# TC37XPD register map
Vendor: Infineon; Series: ATVMC; File version: 100
CPU: other r0p0, little endian, MPU, FPU, vendor SysTick, 4 interrupt priority bits
Registers are 32-bit, read-write, reset 0x0 unless marked. A register's access mark holds for its fields unless they carry their own. Offsets are from the block's base; [hi:lo] are bit positions; {n}, {i} and the like mark numbered series.

## ERAY0 (part 3 of 3) — ERAY
Base 0xF001C000
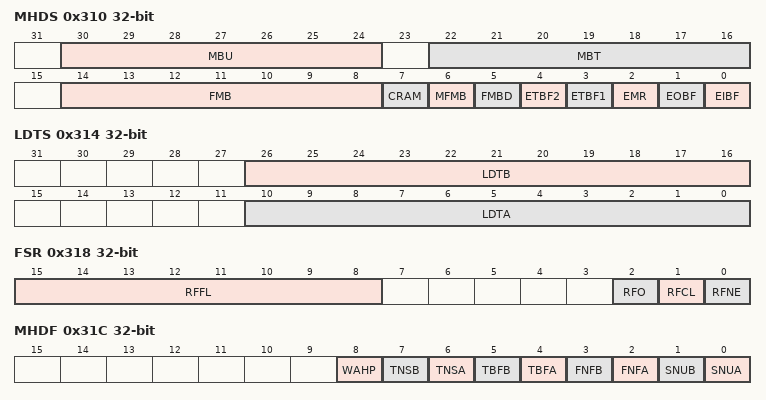
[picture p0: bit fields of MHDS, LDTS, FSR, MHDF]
0x310 MHDS access per field — Message Handler Status resetvalue={Application Reset:0x0}
  [30:24] MBU ro — Message Buffer Updated MBU. Number of Message Buffer that was updated last. For this Message Buffer the respective NDn n 0 31 to NDn n 96 127 and or MBCn n 0 31 to MBCn n 96 127 flag in the New Data Registers NDAT1 to NDAT4 and the Message Buffer Status Changed MBSC1 to MBSC4 registers are also set. MBU is reset when the Communication Controller leaves CONFIG state or enters STARTUP state.
  [22:16] MBT ro — Message Buffer Transmitted MBT. Number of last successfully transmitted Message Buffer. If the Message Buffer is configured for single shot mode the respective TXR flag in the Transmission Request Registers TXRQ1 to TXRQ4 was reset. MBT is reset when the Communication Controller leaves CONFIG state or enters STARTUP state.
  [14:8] FMB ro — Faulty Message Buffer FMB. ECC error occurred when reading from the Message Buffer or when transferring data from Input Buffer or Transient Buffer A or Transient Buffer B to the Message Buffer referenced by MHDS.FMB. Value only valid when one of the flags MHDS.EIBF MHDS.EMR MHDS.ETBF1 MHDS.ETBF2 and flag MHDS.FMBD is set. Updated only after the Host has reset flag MHDS.FMBD.
  [7] CRAM ro — Clear all internal RAM s CRAM. Signals that execution of the CHI command CLEAR RAMS is ongoing all bits of all internal RAM blocks are written to 0 . The bit is set by CHI command CLEAR RAMS.
  [6] MFMB rw — Multiple Faulty Message Buffers detected MFMB
  [5] FMBD rw — Faulty Message Buffer Detected FMBD
  [4] ETBF2 rw — ECC Error Transient Buffer RAM B ETBF2
  [3] ETBF1 rw — ECC Error Transient Buffer RAM A ETBF1
  [2] EMR rw — ECC Error Message RAM EMR
  [1] EOBF rw — ECC Error Output Buffer RAM 1 2 EOBF
  [0] EIBF rw — ECC Error Input Buffer RAM 1 2 EIBF
0x314 LDTS ro — Last Dynamic Transmit Slot resetvalue={Application Reset:0x0}
  [26:16] LDTB — Last Dynamic Transmission Channel B LDTB. Value of vSlotCounter B at the time of the last Frame transmission on channel B in the dynamic segment of this node. It is updated at the end of the dynamic segment and is reset to zero if no Frame was transmitted during the dynamic segment.
  [10:0] LDTA — Last Dynamic Transmission Channel A LDTA. Value of vSlotCounter A at the time of the last Frame transmission on channel A in the dynamic segment of this node. It is updated at the end of the dynamic segment and is reset to zero if no Frame was transmitted during the dynamic segment.
0x318 FSR ro — FIFO Status Register resetvalue={Application Reset:0x0}
  [15:8] RFFL — Receive FIFO Fill Level RFFL. Number of FIFO buffers filled up with new data not yet read by the Host. Maximum value is 128.
  [2] RFO — Receive FIFO Overrun RFO. The flag is set by the Communication Controller when a receive FIFO overrun is detected. When a receive FIFO overrun occurs the oldest message is overwritten with the actual received message. In addition service request flag EIR.RFO is set.The flag is cleared by the next FIFO read access issued by the Host.
  [1] RFCL — Receive FIFO Critical Level RFCL. This flag is set when the receive FIFO fill level RFFL is equal or greater than the critical level as configured by FCL.CL. The flag is cleared by the Communication Controller as soon as RFFL drops below FCL.CL. When RFCL changes from 0 to 1 bit SIR.RFCL is set to 1 and if enabled an service request is generated.
  [0] RFNE — Receive FIFO Not Empty RFNE. This flag is set by the Communication Controller when a received valid Frame data or NULL Frame depending on rejection mask was stored in the FIFO. In addition service request flag SIR.RFNE is set. The bit is reset after the Host has read all message from the FIFO.
0x31C MHDF — Message Handler Constraints Flags resetvalue={Application Reset:0x0}
  [8] WAHP — Write Attempt to Header Partition WAHP. Outside DEFAULT CONFIG and CONFIG state this flag is set by the Communication Controller when the message handler tries to write message data into the Header Partition of the Message RAM due to faulty configuration of a Message Buffer. The write attempt is not executed to protect the Header Partition from unintended write accesses.
  [7] TNSB — Transmission Not Started Channel B TNSB. This flag is set by the CC when the Message Handler was not ready to start a scheduled transmission on channel B at the action point of the configured slot.
  [6] TNSA — Transmission Not Started Channel A TNSA. This flag is set by the CC when the Message Handler was not ready to start a scheduled transmission on channel A at the action point of the configured slot.
  [5] TBFB — Transient Buffer Access Failure B TBFB. This flag is set by the Communication Controller when a read or write access to Transient Buffer B requested by PRT B could not complete within the available time.
  [4] TBFA — Transient Buffer Access Failure A TBFA. This flag is set by the Communication Controller when a read or write access to Transient Buffer A requested by PRT A could not complete within the available time.
  [3] FNFB — Find Sequence Not Finished Channel B FNFB. This flag is set by the Communication Controller when the Message Handler due to overload condition was not able to finish a find sequence scan of Message RAM for matching Message Buffer with respect to channel B.
  [2] FNFA — Find Sequence Not Finished Channel A FNFA. This flag is set by the Communication Controller when the Message Handler due to overload condition was not able to finish a find sequence scan of Message RAM for matching Message Buffer with respect to channel A.
  [1] SNUB — Status Not Updated Channel B SNUB. This flag is set by the Communication Controller when the Message Handler due to overload condition was not able to update a Message Buffer s status MBS with respect to channel B.
  [0] SNUA — Status Not Updated Channel A SNUA. This flag is set by the Communication Controller when the Message Handler due to overload condition was not able to update a Message Buffer s status MBS with respect to channel A.
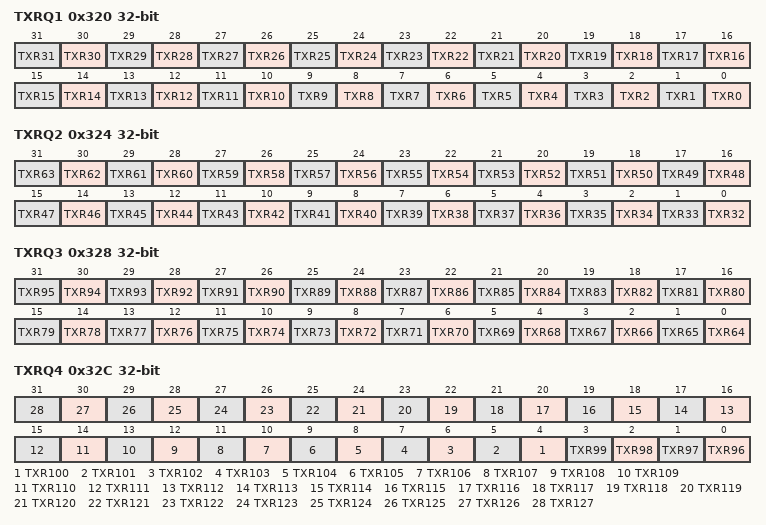
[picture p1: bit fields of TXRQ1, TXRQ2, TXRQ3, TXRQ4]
0x320 TXRQ1 ro — Transmission Request Register 1 resetvalue={Application Reset:0x0}
  [n] TXR{n} (n=0..31) — Transmission Request 31 n 0 31 TXR31. If the flag is set the respective Message Buffer 0 to 31 is ready for transmission respectively transmission of this Message Buffer is in progress. In single shot mode the flags are reset after transmission has completed.
0x324 TXRQ2 ro — Transmission Request Register 2 resetvalue={Application Reset:0x0}
  [n-32] TXR{n} (n=32..63) — Transmission Request 63 n 32 63 TXR63. If the flag is set the respective Message Buffer 32 to 63 is ready for transmission respectively transmission of this Message Buffer is in progress. In single shot mode the flags are reset after transmission has completed.
0x328 TXRQ3 ro — Transmission Request Register 3 resetvalue={Application Reset:0x0}
  [n-64] TXR{n} (n=64..95) — Transmission Request 95 n 64 95 TXR95. If the flag is set the respective Message Buffer 64 to 95 is ready for transmission respectively transmission of this Message Buffer is in progress. In single shot mode the flags are reset after transmission has completed.
0x32C TXRQ4 ro — Transmission Request Register 4 resetvalue={Application Reset:0x0}
  [n-96] TXR{n} (n=96..127) — Transmission Request 127 n 96 127 TXR127. If the flag is set the respective Message Buffer 96 to 127 is ready for transmission respectively transmission of this Message Buffer is in progress. In single shot mode the flags are reset after transmission has completed.
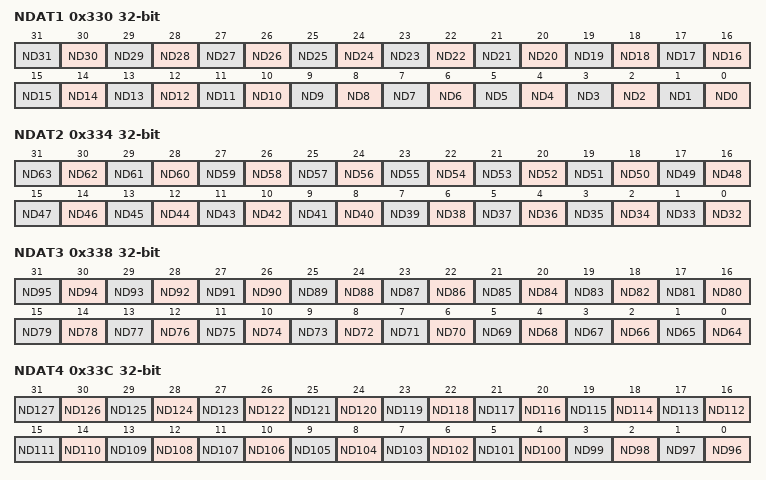
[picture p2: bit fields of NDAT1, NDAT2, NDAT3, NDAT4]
0x330 NDAT1 ro — New Data Register 1 resetvalue={Application Reset:0x0}
  [n] ND{n} (n=0..31) — New Data 31 n 0 31 ND31. The flags are set when a valid received Data Frame matches the Message Buffer s filter configuration independent of the payload length received or the payload length configured for that Message Buffer. The flags are not set after reception of NULL Frames except for Message Buffers belonging to the receive FIFO. An ND flag is reset when the Header Section of the corresponding Message Buffer is reconfigured or when the Data Section has been transferred to the Output Buffer.
0x334 NDAT2 ro — New Data Register 2 resetvalue={Application Reset:0x0}
  [n-32] ND{n} (n=32..63) — New Data 63 n 32 63 ND63. The flags are set when a valid received Data Frame matches the Message Buffer s filter configuration independent of the payload length received or the payload length configured for that Message Buffer. The flags are not set after reception of NULL Frames except for Message Buffers belonging to the receive FIFO. An ND flag is reset when the Header Section of the corresponding Message Buffer is reconfigured or when the Data Section has been transferred to the Output Buffer.
0x338 NDAT3 ro — New Data Register 3 resetvalue={Application Reset:0x0}
  [n-64] ND{n} (n=64..95) — New Data 95 n 64 95 ND95. The flags are set when a valid received Data Frame matches the Message Buffer s filter configuration independent of the payload length received or the payload length configured for that Message Buffer. The flags are not set after reception of NULL Frames except for Message Buffers belonging to the receive FIFO. An ND flag is reset when the Header Section of the corresponding Message Buffer is reconfigured or when the Data Section has been transferred to the Output Buffer.
0x33C NDAT4 ro — New Data Register 4 resetvalue={Application Reset:0x0}
  [n-96] ND{n} (n=96..127) — New Data 127 n 96 127 ND127. The flags are set when a valid received Data Frame matches the Message Buffer s filter configuration independent of the payload length received or the payload length configured for that Message Buffer. The flags are not set after reception of NULL Frames except for Message Buffers belonging to the receive FIFO. An ND flag is reset when the Header Section of the corresponding Message Buffer is reconfigured or when the Data Section has been transferred to the Output Buffer.
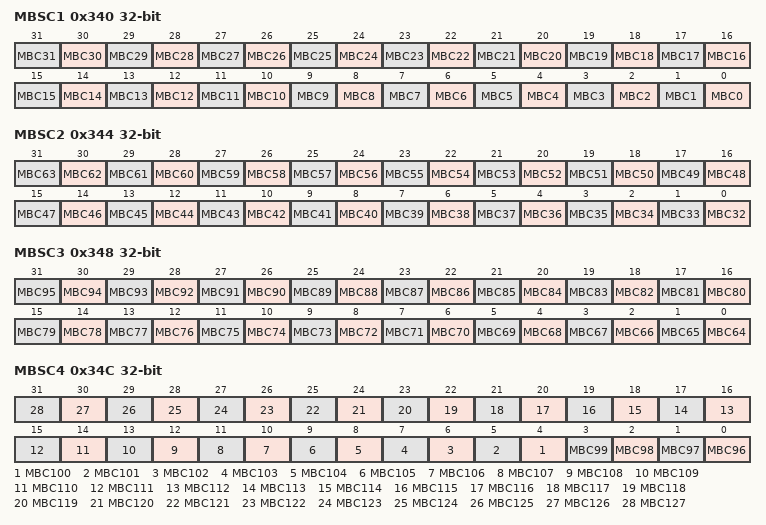
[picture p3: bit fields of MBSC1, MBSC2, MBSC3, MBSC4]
0x340 MBSC1 ro — Message Buffer Status Changed 1 resetvalue={Application Reset:0x0}
  [n] MBC{n} (n=0..31) — Message Buffer Status Changed 31 n 0 31 MBC31. An MBC flags is set whenever the Message Handler changes on of the status flags VFRA VFRB SEOA SEOB CEOA CEOB SVOA SVOB TCIA TCIB ESA ESB MLST FTA FTB in the Header Section see 8220 Message Buffer Status 8221 of the respective Message Buffer 0 to Message Buffer 160 31. The flags are reset when the Header Section of the Message Buffer is reconfigured or when it has been transferred to the Output Buffer.
0x344 MBSC2 ro — Message Buffer Status Changed 2 resetvalue={Application Reset:0x0}
  [n-32] MBC{n} (n=32..63) — Message Buffer Status Changed 63 n 32 63 MBC63. An MBC flags is set whenever the Message Handler changes on of the status flags VFRA VFRB SEOA SEOB CEOA CEOB SVOA SVOB TCIA TCIB ESA ESB MLST FTA FTB in the Header Section see 8220 Message Buffer Status 8221 of the respective Message Buffer 160 32 to Message Buffer 160 63. The flags are reset when the Header Section of the Message Buffer is reconfigured or when it has been transferred to the Output Buffer.
0x348 MBSC3 ro — Message Buffer Status Changed 3 resetvalue={Application Reset:0x0}
  [n-64] MBC{n} (n=64..95) — Message Buffer Status Changed 95 n 64 95 MBC95. An MBC flags is set whenever the Message Handler changes on of the status flags VFRA VFRB SEOA SEOB CEOA CEOB SVOA SVOB TCIA TCIB ESA ESB MLST FTA FTB in the Header Section see 8220 Message Buffer Status 8221 of the respective Message Buffer 160 64 to Message Buffer 160 95. The flags are reset when the Header Section of the Message Buffer is reconfigured or when it has been transferred to the Output Buffer.
0x34C MBSC4 ro — Message Buffer Status Changed 4 resetvalue={Application Reset:0x0}
  [n-96] MBC{n} (n=96..127) — Message Buffer Status Changed 127 n 96 127 MBC127. An MBC flags is set whenever the Message Handler changes on of the status flags VFRA VFRB SEOA SEOB CEOA CEOB SVOA SVOB TCIA TCIB ESA ESB MLST FTA FTB in the Header Section see 8220 Message Buffer Status 8221 of the respective Message Buffer 160 96 to Message Buffer 160 127. The flags are reset when the Header Section of the Message Buffer is reconfigured or when it has been transferred to the Output Buffer.
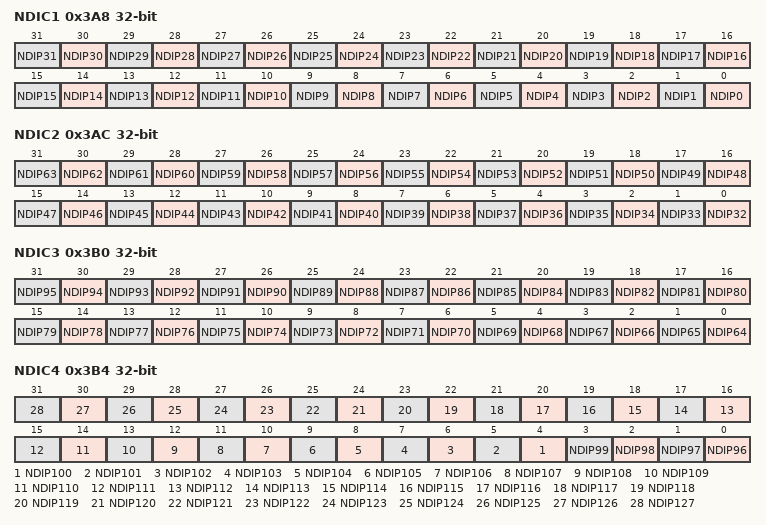
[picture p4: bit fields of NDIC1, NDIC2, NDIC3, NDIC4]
0x3A8 NDIC1 — New Data Interrupt Control 1 resetvalue={Application Reset:0x0}
  [n] NDIP{n} (n=0..31) — New Data Interrupt Pointer 31 n 0 31 NDIP31. NDIPn determines the interrupt NDAT0SRC or NDAT1SRC of the service request output that becomes active on a New Data Flag becoming active.
0x3AC NDIC2 — New Data Interrupt Control 2 resetvalue={Application Reset:0x0}
  [n-32] NDIP{n} (n=32..63) — New Data Interrupt Pointer 63 n 32 63 NDIP63. NDIPn determines the interrupt NDAT0SRC or NDAT1SRC of the service request output that becomes active on a New Data Flag becoming active.
0x3B0 NDIC3 — New Data Interrupt Control 3 resetvalue={Application Reset:0x0}
  [n-64] NDIP{n} (n=64..95) — New Data Interrupt Pointer 95 n 64 95 NDIP95. NDIPn determines the interrupt NDAT0SRC or NDAT1SRC of the service request output that becomes active on a New Data Flag becoming active.
0x3B4 NDIC4 — New Data Interrupt Control 4 resetvalue={Application Reset:0x0}
  [n-96] NDIP{n} (n=96..127) — New Data Interrupt Pointer 127 n 96 127 NDIP127. NDIPn determines the interrupt NDAT0SRC or NDAT1SRC of the service request output that becomes active on a New Data Flag becoming active.
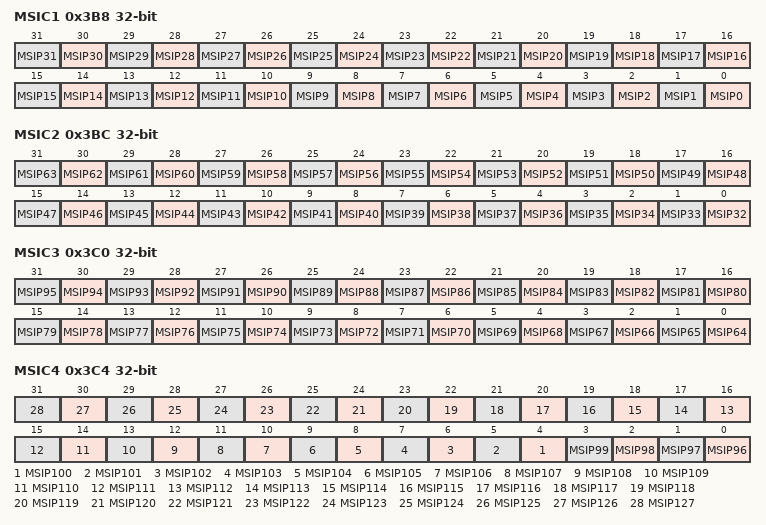
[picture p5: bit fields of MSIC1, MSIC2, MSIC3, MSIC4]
0x3B8 MSIC1 — Message Buffer Status Changed Interrupt Control 1 resetvalue={Application Reset:0x0}
  [n] MSIP{n} (n=0..31) — Message Buffer Status Changed Interrupt Pointer 31 n 0 31 MSIP31. MSIPn determines the interrupt MBSC0SRC or MBSC1SRC of the service request output that becomes active on a Message Buffer Status Changed Flag becoming active.
0x3BC MSIC2 — Message Buffer Status Changed Interrupt Control 2 resetvalue={Application Reset:0x0}
  [n-32] MSIP{n} (n=32..63) — Message Buffer Status Changed Interrupt Pointer 63 n 32 63 MSIP63. MSIPn determines the interrupt MBSC0SRC or MBSC1SRC of the service request output that becomes active on a Message Buffer Status Changed Flag becoming active.
0x3C0 MSIC3 — Message Buffer Status Changed Interrupt Control 3 resetvalue={Application Reset:0x0}
  [n-64] MSIP{n} (n=64..95) — Message Buffer Status Changed Interrupt Pointer 95 n 64 95 MSIP95. MSIPn determines the interrupt MBSC0SRC or MBSC1SRC of the service request output that becomes active on a Message Buffer Status Changed Flag becoming active.
0x3C4 MSIC4 — Message Buffer Status Changed Interrupt Control 4 resetvalue={Application Reset:0x0}
  [n-96] MSIP{n} (n=96..127) — Message Buffer Status Changed Interrupt Pointer 127 n 96 127 MSIP127. MSIPn determines the interrupt MBSC0SRC or MBSC1SRC of the service request output that becomes active on a Message Buffer Status Changed Flag becoming active.
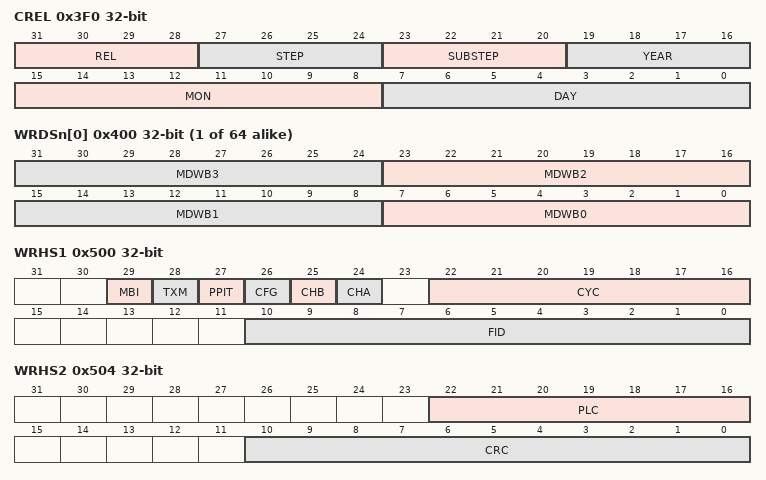
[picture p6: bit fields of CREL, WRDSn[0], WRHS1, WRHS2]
0x3F0 CREL ro reset not defined — Core Release Register resetvalue={Application Reset:0x0}
  [31:28] REL — Core Release REL. One digit BCD coded.
  [27:24] STEP — Step of Core Release STEP. One digits BCD coded.
  [23:20] SUBSTEP — Sub Step of Core Release SUBSTEP. One digits BCD coded.
  [19:16] YEAR — Design Time Stamp Year YEAR. One digit BCD coded.
  [15:8] MON — Design Time Stamp Month MON. Two digits BCD coded.
  [7:0] DAY — Design Time Stamp Day DAY. Two digits BCD coded.
0x3F4 ENDN ro reset 0x87654321 — Endian Register resetvalue={Application Reset:0x087654321}
  [31:0] ETV — Endianness Test Value ETV. The endianness test value.
{0x400+4i} WRDSn[{i}] (i=0..63) — Write Data Section 01 resetvalue={Application Reset:0x0}
  [8n+7:8n] MDWB{n} (n=0..3) — 32 Bit Word nn Byte {n} MDWB{n}
0x500 WRHS1 — Write Header Section 1 resetvalue={Application Reset:0x0}
  [29] MBI — Message Buffer Service Request MBI. This bit enables the receive transmit service request for the corresponding Message Buffer. After a dedicated receive buffer has been updated by the Message Handler flag SIR.RXI and or SIR.MBSI in the Status Service Request register are set. After a transmission has completed flag SIR.TXI is set.
  [28] TXM — Transmission Mode TXM. This bit is used to select the transmission mode see 8220 Transmit Buffers 8221 .
  [27] PPIT — Payload Preamble Indicator Transmit PPIT. This bit is used to control the state of the Payload Preamble Indicator in transmit Frames. If the bit is set in a static Message Buffer the respective Message Buffer holds Network Management information. If the bit is set in a dynamic Message Buffer the first two byte of the Payload Segment may be used for message ID filtering by the receiver. Message ID filtering of received FlexRay 8482 Frames is not supported by the E Ray module but can be done by the Host.
  [26] CFG — Message Buffer Direction Configuration Bit CFG. This bit is used to configure the corresponding buffer as a transmit buffer or as a receive buffer. For Message Buffers belonging to the receive FIFO the bit is not evaluated.
  [25] CHB — Channel Filter Control B CHB. The channel filtering field B associated with the buffer serves of channel B as a filter for receive buffers and as a control field for transmit buffers
  [24] CHA — Channel Filter Control A CHA. The channel filtering field A associated with the buffer serves of channel A as a filter for receive buffers and as a control field for transmit buffers
  [22:16] CYC — Cycle Code CYC. The 7 bit cycle code determines the cycle set used for cycle counter filtering. For details about the configuration of the cycle code see Section 160 quot Cycle Counter Filtering quot .
  [10:0] FID — Frame ID FID. Frame ID of the selected Message Buffer. The Frame ID defines the slot number for transmission reception of the respective message. Message Buffers with Frame ID 0 are considered as not valid.
0x504 WRHS2 — Write Header Section 2 resetvalue={Application Reset:0x0}
  [22:16] PLC — Payload Length Configured PLC. Length of Data Section number of 2 byte words as configured by the Host. During static segment the static Frame payload length as configured by MHDC.SFDL in the MHD Configuration Register defines the payload length for all static Frames. If the payload length configured by PLC is shorter than this value padding byte are inserted to ensure that Frames have proper physical length. The padding pattern is logical zero.
  [10:0] CRC — Header CRC vRF Header HeaderCRC CRC. Receive Buffer Configuration not required Transmit Buffer Header CRC calculated and configured by the Host. For calculation of the Header CRC the payload length of the Frame send on the bus has to be considered. In static segment the payload length of all Frames is configured by MHDC.SFDL.
0x508 WRHS3 — Write Header Section 3 resetvalue={Application Reset:0x0}
  [10:0] DP — Data Pointer DP. Pointer to the first 32 bit word of the Data Section of the addressed Message Buffer in the Message RAM.
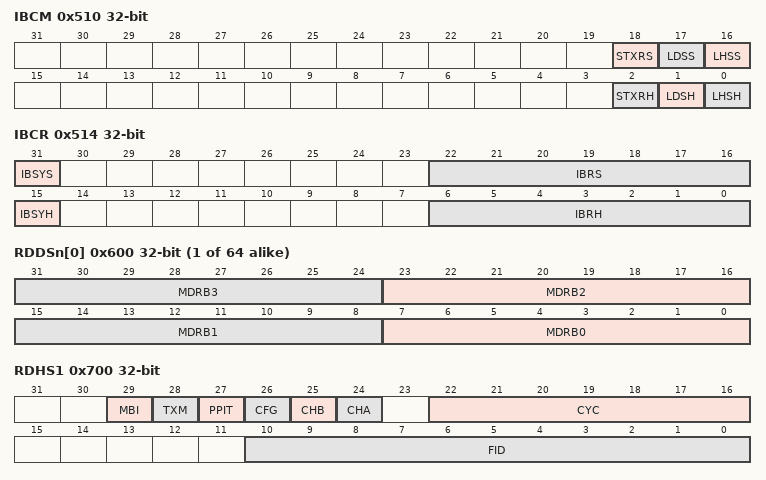
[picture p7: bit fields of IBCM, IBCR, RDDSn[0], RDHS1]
0x510 IBCM access per field — Input Buffer Command Mask resetvalue={Application Reset:0x0}
  [18] STXRS ro — Transmission Request Shadow STXRS. If this bit is set to 1 the Transmission Request flag TXRQ1.TXRn n 0 31 to TXRQ4.TXRn n 96 127 for the selected Message Buffer is set in the Transmission Request Registers to release the Message Buffer for transmission. In single shot mode the flag is cleared by the Communication Controller after transmission has completed. TXRQ1.TXRn n 0 31 to TXRQ4.TXRn n 96 127 are evaluated for transmit buffer only.
  [17] LDSS ro — Load Data Section Shadow LDSS
  [16] LHSS ro — Load Header Section Shadow LHSS
  [2] STXRH rw — Set Transmission Request Host STXRH. If this bit is set to 1 the Transmission Request flag TXRQ1.TXRn n 0 31 to TXRQ4.TXRn n 96 127 for the selected Message Buffer is set in the Transmission Request Registers to release the Message Buffer for transmission. In single shot mode the flag is cleared by the Communication Controller after transmission has completed. TXRQ1.TXRn n 0 31 to TXRQ4.TXRn n 96 127 are evaluated for transmit buffer only.
  [1] LDSH rw — Load Data Section Host LDSH
  [0] LHSH rw — Load Header Section Host LHSH
0x514 IBCR access per field — Input Buffer Command Request resetvalue={Application Reset:0x0}
  [31] IBSYS ro — Input Buffer Busy Shadow IBSYS. Set to 1 after writing IBRH. When the transfer between IBF Shadow and the Message RAM has completed IBSYS is set back to 0.
  [22:16] IBRS ro — Input Buffer Request Shadow IBRS. Number of the target Message Buffer actually updated lately updated. Valid values are 00 H to 7F H 0 127 .
  [15] IBSYH ro — Input Buffer Busy Host IBSYH. Set to 1 by writing IBRH while IBSYS is still 1. After the ongoing transfer between IBF Shadow and the Message RAM has completed the IBSYH is set back to 0.
  [6:0] IBRH rw — Input Buffer Request Host IBRH. Selects the target Message Buffer in the Message RAM for data transfer from Input Buffer. Valid values are 00 H to 7F H 0 127 .
{0x600+4i} RDDSn[{i}] (i=0..63) ro — Read Data Section 01 resetvalue={Application Reset:0x0}
  [8n+7:8n] MDRB{n} (n=0..3) — 32 Bit Word nn Byte {n} MDRB{n}
0x700 RDHS1 ro — Read Header Section 1 resetvalue={Application Reset:0x0}
  [29] MBI — Message Buffer Service Request MBI
  [28] TXM — Transmission Mode TXM
  [27] PPIT — Payload Preamble Indicator Transmit PPIT
  [26] CFG — Message Buffer Direction Configuration Bit CFG
  [25] CHB — Channel Filter Control B CHB
  [24] CHA — Channel Filter Control A CHA
  [22:16] CYC — Cycle Code CYC
  [10:0] FID — Frame ID FID
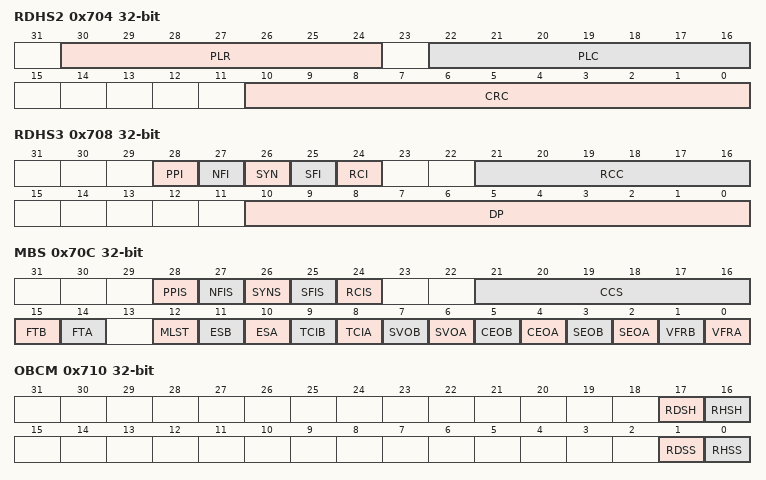
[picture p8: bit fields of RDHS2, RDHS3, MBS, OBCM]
0x704 RDHS2 ro — Read Header Section 2 resetvalue={Application Reset:0x0}
  [30:24] PLR — Payload Length Received vRF Header Length PLR. Payload length value updated from received Data Frame exception if Message Buffer belongs to the receive FIFO PLR is also updated from received NULL Frames . When a message is stored into a Message Buffer the following behavior with respect to payload length received and payload length configured is implemented PLR gt PLC The payload data stored in the Message Buffer is truncated to the payload length configured for even PLC or else truncated to PLC 1. PLR PLC The received payload data is stored into the Message Buffers Data Section. The remaining data bytes of the Data Section as configured by PLC are filled with undefined data. PLR 0 The Message Buffer s Data Section is filled with undefined data. PLC 0 Message Buffer has no Data Section configured. No data is stored into the Message Buffer s Data Section.
  [22:16] PLC — Payload Length Configured PLC. Length of Data Section number of 2 byte words as configured by the Host.
  [10:0] CRC — Header CRC vRF Header HeaderCRC CRC. Receive Buffer Configuration not required. Header CRC updated from receive Data Frames. Transmit Buffer Header CRC calculated and configured by the Host
0x708 RDHS3 ro — Read Header Section 3 resetvalue={Application Reset:0x0}
  [28] PPI — Payload Preamble Indicator vRF Header PPIndicator PPI. The payload preamble indicator defines whether a Network Management vector or message ID is contained within the Payload Segment of the received Frame.
  [27] NFI — NULL Frame Indicator vRF Header NFIndicator NFI. Is set to 1 after storage of the first received Data Frame.
  [26] SYN — SYNC Frame Indicator vRF Header SyFIndicator SYN. A SYNC Frame is marked by the SYNC Frame indicator.
  [25] SFI — Startup Frame Indicator vRF Header SuFIndicator SFI. A Startup Frame is marked by the Startup Frame indicator.
  [24] RCI — Received on Channel Indicator vSS Channel RCI. Indicates the channel from which the received Data Frame was taken to update the respective receive buffer.
  [21:16] RCC — Receive Cycle Count vRF Header CycleCount RCC. Cycle counter value updated from received Data Frame.
  [10:0] DP — Data Pointer DP. Pointer to the first 32 bit word of the Data Section of the addressed Message Buffer in the Message RAM.
0x70C MBS ro — Message Buffer Status resetvalue={Application Reset:0x0}
  [28] PPIS — Payload Preamble Indictor Status vRF Header PPIndicator PPIS. The payload preamble indicator defines whether a Network Management vector or message ID is contained within the Payload Segment of the received Frame. For receive buffers CFG 0 the PPIS is updated from both valid data and NULL Frames. If no valid Frame was received the previous value is maintained. For transmit buffers the flags have no meaning and should be ignored.
  [27] NFIS — NULL Frame Indicator Status vRF Header NFIndicator NFIS. If reset to 0 the Payload Segment of the received Frame contains no usable data. For receive buffers CFG 0 the NFIS is updated from both valid data and NULL Frames. If no valid Frame was received the previous value is maintained. For transmit buffers the flags have no meaning and should be ignored.
  [26] SYNS — SYNC Frame Indicator Status vRF Header SyFIndicator SYNS. A SYNC Frame is marked by the SYNC Frame indicator. For receive buffers CFG 0 the SYNS is updated from both valid data and NULL Frames. If no valid Frame was received the previous value is maintained. For transmit buffers the flags have no meaning and should be ignored.
  [25] SFIS — Startup Frame Indicator Status vRF Header SuFIndicator SFIS. A Startup Frame is marked by the Startup Frame indicator. For receive buffers CFG 0 the SFIS is updated from both valid data and NULL Frames. If no valid Frame was received the previous value is maintained. For transmit buffers the flags have no meaning and should be ignored.
  [24] RCIS — Received on Channel Indicator Status vSS Channel RCIS. Indicates the channel on which the Frame was received. For receive buffers CFG 0 the RCIS is updated from both valid data and NULL Frames. If no valid Frame was received the previous value is maintained. For transmit buffers the flags have no meaning and should be ignored.
  [21:16] CCS — Cycle Count Status CCS. Cycle Count when status MBS register has been updated.
  [15] FTB — Frame Transmitted on Channel B FTB. Indicates that this node has transmitted a Data Frame in the assigned slot on channel B. The FlexRay protocol specification requires that FTB can only be reset by the Host. Therefore the Cycle Count Status CCS for these bits is only valid for the cycle where the bits are set to 1
  [14] FTA — Frame Transmitted on Channel A FTA. Indicates that this node has transmitted a Data Frame in the assigned slot on channel A. The FlexRay protocol specification requires that FTA can only be reset by the Host. Therefore the Cycle Count Status CCS for these bits is only valid for the cycle where the bits are set to 1
  [12] MLST — Message Lost MLST. The flag is set in case the Host did not read the message before the Message Buffer was updated from a received Data Frame. Not affected by reception of NULL Frames except for Message Buffers belonging to the receive FIFO. The flag is reset by a Host write to the Message Buffer via IBF or when a new message is stored into the Message Buffer after the Message Buffers ND flag was reset by reading out the Message Buffer via OBF.
  [11] ESB — Empty Slot Channel B ESB. In an empty slot there is no activity detected on the bus. The condition is checked in static and dynamic slots.
  [10] ESA — Empty Slot Channel A ESA. In an empty slot there is no activity detected on the bus. The condition is checked in static and dynamic slots.
  [9] TCIB — Transmission Conflict Indication Channel B vSS TxConflictB TCIB. A transmission conflict indication is set if a transmission conflict has occurred on channel B.
  [8] TCIA — Transmission Conflict Indication Channel A vSS TxConflictA TCIA. A transmission conflict indication is set if a transmission conflict has occurred on channel A.
  [7] SVOB — Slot Boundary Violation Observed on Channel B vSS BViolationB SVOB. A slot boundary violation channel active at the start or at the end of the assigned slot was observed on channel B.
  [6] SVOA — Slot Boundary Violation Observed on Channel A vSS BViolationA SVOA. A slot boundary violation channel active at the start or at the end of the assigned slot was observed on channel A.
  [5] CEOB — Content Error Observed on Channel B vSS ContentErrorB CEOB. A content error was observed in the assigned slot on channel B.
  [4] CEOA — Content Error Observed on Channel A vSS ContentErrorA CEOA. A content error was observed in the assigned slot on channel A.
  [3] SEOB — Syntax Error Observed on Channel B vSS SyntaxErrorB SEOB. A syntax error was observed in the assigned slot on channel B.
  [2] SEOA — Syntax Error Observed on Channel A vSS SyntaxErrorA SEOA. A syntax error was observed in the assigned slot on channel A.
  [1] VFRB — Valid Frame Received on Channel B vSS ValidFrameB VFRB. A valid Frame indication is set if a valid Frame was received on channel B.
  [0] VFRA — Valid Frame Received on Channel A vSS ValidFrameA VFRA. A valid Frame indication is set if a valid Frame was received on channel A.
0x710 OBCM access per field — Output Buffer Command Mask resetvalue={Application Reset:0x0}
  [17] RDSH ro — Read Data Section Host RDSH
  [16] RHSH ro — Read Header Section Host RHSH
  [1] RDSS rw — Read Data Section Shadow RDSS
  [0] RHSS rw — Read Header Section Shadow RHSS
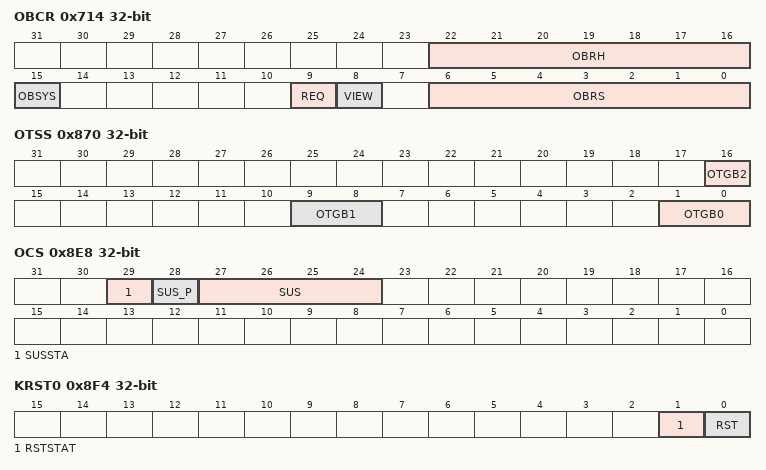
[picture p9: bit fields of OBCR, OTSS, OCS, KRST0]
0x714 OBCR access per field — Output Buffer Command Request resetvalue={Application Reset:0x0}
  [22:16] OBRH ro — Output Buffer Request Host OBRH. Number of Message Buffer currently accessible by the Host via RDHS1 to RDHS3 MBS and RDDSnn nn 01 64 . By setting OBCR.VIEW OBF Shadow and OBF Host are swapped and the transferred Message Buffer is accessible by the Host. Valid values are 00 H to 7F H 01 to 127 .
  [15] OBSYS ro — Output Buffer Busy Shadow OBSYS. Set to 1 after setting bit OBCR.REQ. When the transfer between the Message RAM and OBF Shadow has completed OBCR.OBSYS is cleared again.
  [9] REQ rw — Request Message RAM Transfer REQ. Requests transfer of Message Buffer addressed by OBCR.OBRS from Message RAM to OBF Shadow. Only writeable while OBCR.OBSYS 0.
  [8] VIEW rw — View Shadow Buffer VIEW. Toggles between OBF Shadow and OBF Host. Only writeable while OBCR.OBSYS 0.
  [6:0] OBRS rw — Output Buffer Request Shadow OBRS. Number of source Message Buffer to be transferred from the Message RAM to OBF Shadow. Valid values are 00 H to 7F H 0 to 127 . If the number of the first Message Buffer of the receive FIFO is written to this register the Message Handler transfers the Message Buffer addressed by the GET Index Register GIDX 8220 FIFO Function 8221 to OBF Shadow.
0x870 OTSS — OCDS Trigger Set Select resetvalue={Application Reset:0x0}
  [16] OTGB2 — Trigger Set for OTGB2 OTGB2
  [9:8] OTGB1 — Trigger Set for OTGB1 OTGB1
  [1:0] OTGB0 — Trigger Set for OTGB0 OTGB0
0x8E8 OCS access per field — OCDS Control and Status resetvalue={Debug Reset:0x0}
  [29] SUSSTA ro — Suspend State SUSSTA
  [28] SUS_P wo — SUS Write Protection SUS P. SUS is only written when SUS P is 1 otherwise unchanged. Read as 0.
  [27:24] SUS rw — OCDS Suspend Control SUS. Controls the sensitivity to the suspend signal coming from the OCDS Trigger Switch OTGS
0x8EC KRSTCLR wo — Kernel Reset Status Clear Register resetvalue={Application Reset:0x0}
  [0] CLR — Kernel Reset Status Clear CLR. Read always as 0.
0x8F0 KRST1 — Kernel Reset Register 1 resetvalue={Application Reset:0x0}
  [0] RST — Kernel Reset RST. This reset bit can be used to request for a kernel reset. The kernel reset will be executed if the reset bits of both kernel reset registers is set. The RST bit will be cleared re set to 0 by the BPI FPI after the kernel reset was executed.
0x8F4 KRST0 access per field — Kernel Reset Register 0 resetvalue={Application Reset:0x0}
  [1] RSTSTAT ro — Kernel Reset Status RSTSTAT. This bit indicates wether a kernel reset was executed or not. This bit is set by the BPI FPI after the execution of a kernel reset in the same clock cycle both reset bits. This bit can be cleared by writing with 180 1 180 to the CLR bit in the related KRSTCLR register.
  [0] RST rw — Kernel Reset RST. This reset bit can be used to request for a kernel reset. The kernel reset will be executed if the reset bits of both kernel registers are set. The RST bit will be cleared re set to 180 0 180 by the BPI FPI after the kernel reset was executed.
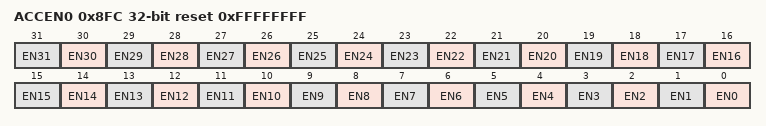
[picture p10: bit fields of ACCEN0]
0x8FC ACCEN0 reset 0xFFFFFFFF — Access Enable Register 0 resetvalue={Application Reset:0x0FFFFFFFF}
  [n] EN{n} (n=0..31) — Access Enable for Master TAG ID 31 EN31. This bit enables write access to the module kernel addresses for transactions with the Master TAG ID n
